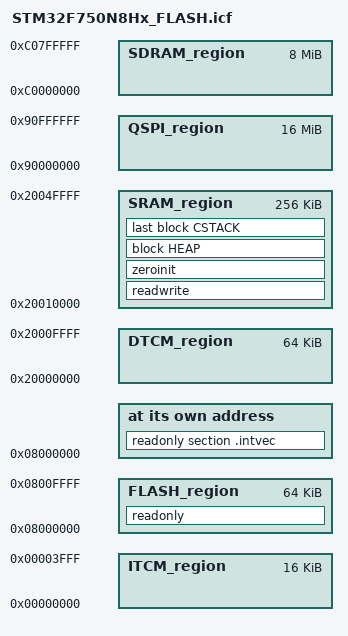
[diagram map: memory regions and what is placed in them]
/*-Specials-*/
define symbol __ICFEDIT_intvec_start__ = 0x08000000;

/*-Memory Regions-*/
define symbol ITCM_start         = 0x00000000;
define symbol ITCM_end           = 0x00003FFF;

define symbol FLASH_start        = 0x08000000;
define symbol FLASH_end          = 0x0800FFFF;

define symbol QSPI_start         = 0x90000000;
define symbol QSPI_end           = 0x90FFFFFF;

define symbol DTCM_start         = 0x20000000;
define symbol DTCM_end           = 0x2000FFFF;

define symbol SRAM_start         = 0x20010000;
define symbol SRAM_end           = 0x2004FFFF;

define symbol SDRAM_start        = 0xC0000000;
define symbol SDRAM_end          = 0xC07FFFFF;

/*-Sizes-*/
define symbol __ICFEDIT_size_heap__      = 0x400;
define symbol __ICFEDIT_size_cstack__    = 0x800;

/* Define the memory addresable size as 4GB */
define memory mem with size = 4G;

/* Define all memory regions */
define region ITCM_region          = mem:[from ITCM_start to ITCM_end];
define region FLASH_region         = mem:[from FLASH_start to FLASH_end];
define region QSPI_region          = mem:[from QSPI_start to QSPI_end];
define region DTCM_region          = mem:[from DTCM_start to DTCM_end];
define region SRAM_region          = mem:[from SRAM_start to SRAM_end];
define region SDRAM_region         = mem:[from SDRAM_start to SDRAM_end];

/* Define reserved empty blocks */
define block HEAP                      with alignment = 8, size = __ICFEDIT_size_heap__ { };
define block CSTACK                    with alignment = 8, size = __ICFEDIT_size_cstack__ { };

/* Initialize by copy the readwrite section */
initialize by copy { readwrite };

/* Do not initialize sections marked with .noinit */
do not initialize  { section .noinit };

/* The startup code goes first into FLASH */
place at address mem:__ICFEDIT_intvec_start__ { readonly section .intvec };

/* The program code and other data goes into FLASH */
place in FLASH_region        { readonly };

/* Initialized and uninitialized data sections goes into RAM, load LMA copy after code */
place in SRAM_region         { readwrite, zeroinit, block HEAP, last block CSTACK };
